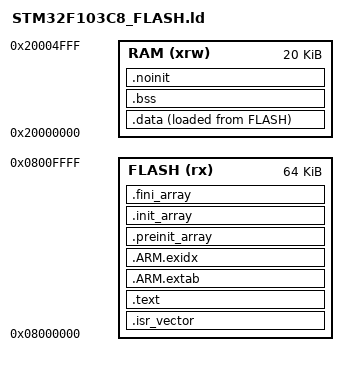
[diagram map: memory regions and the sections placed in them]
/* C8T6 实测64KB Flash、20KB SRAM；不借用部分克隆芯片可能存在的额外Flash。 */
ENTRY(Reset_Handler)
MEMORY { FLASH (rx) : ORIGIN = 0x08000000, LENGTH = 64K
         RAM (xrw) : ORIGIN = 0x20000000, LENGTH = 20K }
_estack = ORIGIN(RAM) + LENGTH(RAM);
SECTIONS {
 .isr_vector : { . = ALIGN(4); KEEP(*(.isr_vector)) } > FLASH
 .text : { . = ALIGN(4); *(.text*) *(.rodata*) KEEP(*(.init)) KEEP(*(.fini)) . = ALIGN(4); _etext = .; } > FLASH
 .ARM.extab : { *(.ARM.extab*) } > FLASH
 .ARM.exidx : { __exidx_start = .; *(.ARM.exidx*) __exidx_end = .; } > FLASH
 .preinit_array : { PROVIDE_HIDDEN(__preinit_array_start = .); KEEP(*(.preinit_array*)) PROVIDE_HIDDEN(__preinit_array_end = .); } > FLASH
 .init_array : { PROVIDE_HIDDEN(__init_array_start = .); KEEP(*(SORT(.init_array.*))) KEEP(*(.init_array*)) PROVIDE_HIDDEN(__init_array_end = .); } > FLASH
 .fini_array : { PROVIDE_HIDDEN(__fini_array_start = .); KEEP(*(SORT(.fini_array.*))) KEEP(*(.fini_array*)) PROVIDE_HIDDEN(__fini_array_end = .); } > FLASH
 _sidata = LOADADDR(.data);
 .data : { . = ALIGN(4); _sdata = .; *(.data*) . = ALIGN(4); _edata = .; } > RAM AT> FLASH
 .bss (NOLOAD) : { . = ALIGN(4); _sbss = .; *(.bss*) *(COMMON) . = ALIGN(4); _ebss = .; } > RAM
 .noinit (NOLOAD) : { . = ALIGN(4); *(.noinit*) . = ALIGN(4); } > RAM
 . = ALIGN(8); _end = .; end = .;
 /* 明确保留4KB主栈，编译期发现RAM不足，不等到上板随机HardFault。无动态堆。 */
 ASSERT(_end <= _estack - 4096, "C8 SRAM insufficient: reserve 4KB stack")
 /DISCARD/ : { *(.note*) *(.comment*) }
}
